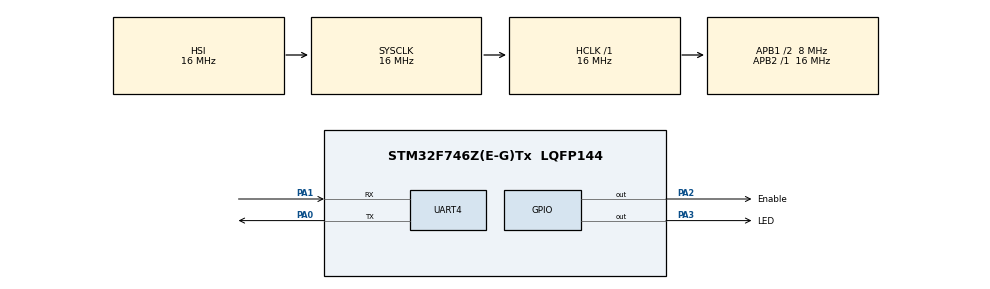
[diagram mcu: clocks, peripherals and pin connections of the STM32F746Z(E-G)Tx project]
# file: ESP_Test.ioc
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Mcu.Family=STM32F7
Mcu.Name=STM32F746Z(E-G)Tx
Mcu.Package=LQFP144
NVIC.PriorityGroup=NVIC_PRIORITYGROUP_4
PA0/WKUP.Mode=Asynchronous
PA0/WKUP.Signal=UART4_TX
PA1.Mode=Asynchronous
PA1.Signal=UART4_RX
PA2.GPIO_Label=Enable 
PA2.Signal=GPIO_Output
PA3.GPIO_Label=LED
PA3.Signal=GPIO_Output
ProjectManager.HeapSize=0x200
ProjectManager.StackSize=0x400
ProjectManager.TargetToolchain=SW4STM32
RCC.48MHZClocksFreq_Value=24000000
RCC.AHBFreq_Value=16000000
RCC.APB1CLKDivider=RCC_HCLK_DIV2
RCC.APB1Freq_Value=8000000
RCC.APB1TimFreq_Value=16000000
RCC.APB2Freq_Value=16000000
RCC.APB2TimFreq_Value=16000000
RCC.CortexFreq_Value=16000000
RCC.HCLKFreq_Value=16000000
RCC.HSE_VALUE=16000000
RCC.HSI_VALUE=16000000
RCC.LSE_VALUE=32768
RCC.PLLMUL=RCC_PLL_MUL9
RCC.PRESCALERUSB=RCC_USBCLKSOURCE_PLL_DIV1_5
RCC.SYSCLKFreq_VALUE=16000000
RCC.SYSCLKSourceVirtual=RCC_SYSCLKSOURCE_PLLCLK
RCC.USBFreq_Value=96000000
RCC.VCOOutputFreq_Value=192000000
UART4.WordLength=UART_WORDLENGTH_8B
board=NUCLEO-F746ZG

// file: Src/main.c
/**
  ******************************************************************************
  * File Name          : main.c
  * Description        : Main program body
  ******************************************************************************
  *
  * COPYRIGHT(c) 2016 STMicroelectronics
  *
  * Redistribution and use in source and binary forms, with or without modification,
  * are permitted provided that the following conditions are met:
  *   1. Redistributions of source code must retain the above copyright notice,
  *      this list of conditions and the following disclaimer.
  *   2. Redistributions in binary form must reproduce the above copyright notice,
  *      this list of conditions and the following disclaimer in the documentation
  *      and/or other materials provided with the distribution.
  *   3. Neither the name of STMicroelectronics nor the names of its contributors
  *      may be used to endorse or promote products derived from this software
  *      without specific prior written permission.
  *
  * THIS SOFTWARE IS PROVIDED BY THE COPYRIGHT HOLDERS AND CONTRIBUTORS "AS IS"
  * AND ANY EXPRESS OR IMPLIED WARRANTIES, INCLUDING, BUT NOT LIMITED TO, THE
  * IMPLIED WARRANTIES OF MERCHANTABILITY AND FITNESS FOR A PARTICULAR PURPOSE ARE
  * DISCLAIMED. IN NO EVENT SHALL THE COPYRIGHT HOLDER OR CONTRIBUTORS BE LIABLE
  * FOR ANY DIRECT, INDIRECT, INCIDENTAL, SPECIAL, EXEMPLARY, OR CONSEQUENTIAL
  * DAMAGES (INCLUDING, BUT NOT LIMITED TO, PROCUREMENT OF SUBSTITUTE GOODS OR
  * SERVICES; LOSS OF USE, DATA, OR PROFITS; OR BUSINESS INTERRUPTION) HOWEVER
  * CAUSED AND ON ANY THEORY OF LIABILITY, WHETHER IN CONTRACT, STRICT LIABILITY,
  * OR TORT (INCLUDING NEGLIGENCE OR OTHERWISE) ARISING IN ANY WAY OUT OF THE USE
  * OF THIS SOFTWARE, EVEN IF ADVISED OF THE POSSIBILITY OF SUCH DAMAGE.
  *
  ******************************************************************************
  */
#include "stm32f7xx_hal.h"
#include"stdlib.h"

UART_HandleTypeDef huart4;

/* USER CODE BEGIN PV */
/* Private variables ---------------------------------------------------------*/

/* USER CODE END PV */

void SystemClock_Config(void);
void Error_Handler(void);
static void MX_GPIO_Init(void);
static void MX_UART4_Init(void);

/* USER CODE BEGIN PFP */
/* Private function prototypes -----------------------------------------------*/

/* USER CODE END PFP */

/* USER CODE BEGIN 0 */
void Activety(void);
void EnableModule(void);
void DisableModule(void);
void TestModule(void);
void SetMode(void);
void GetcurrentMode(void);

/* USER CODE END 0 */

int main(void)
{

	/* Enable I-Cache-------------------------------------------------------------*/
	 SCB_EnableICache();
	/* Enable D-Cache-------------------------------------------------------------*/
	SCB_EnableDCache();
  /* MCU Configuration----------------------------------------------------------*/

  /* Reset of all peripherals, Initializes the Flash interface and the Systick. */
  HAL_Init();

  /* Configure the system clock */
  SystemClock_Config();

  /* Initialize all configured peripherals */
  MX_GPIO_Init();
  MX_UART4_Init();

  /* USER CODE BEGIN 2 */
  Activety();
  EnableModule();
  TestModule();
  DisableModule();
  Activety();
  /* USER CODE END 2 */

  /* Infinite loop */
  while (1)
  {

  }

}

/** System Clock Configuration
*/
void SystemClock_Config(void)
{

  RCC_OscInitTypeDef RCC_OscInitStruct;
  RCC_ClkInitTypeDef RCC_ClkInitStruct;
  RCC_PeriphCLKInitTypeDef PeriphClkInitStruct;

  __HAL_RCC_PWR_CLK_ENABLE();

  __HAL_PWR_VOLTAGESCALING_CONFIG(PWR_REGULATOR_VOLTAGE_SCALE3);

  RCC_OscInitStruct.OscillatorType = RCC_OSCILLATORTYPE_HSI;
  RCC_OscInitStruct.HSIState = RCC_HSI_ON;
  RCC_OscInitStruct.HSICalibrationValue = 16;
  RCC_OscInitStruct.PLL.PLLState = RCC_PLL_NONE;
  if (HAL_RCC_OscConfig(&RCC_OscInitStruct) != HAL_OK)
  {
    Error_Handler();
  }

  RCC_ClkInitStruct.ClockType = RCC_CLOCKTYPE_HCLK|RCC_CLOCKTYPE_SYSCLK
                              |RCC_CLOCKTYPE_PCLK1|RCC_CLOCKTYPE_PCLK2;
  RCC_ClkInitStruct.SYSCLKSource = RCC_SYSCLKSOURCE_HSI;
  RCC_ClkInitStruct.AHBCLKDivider = RCC_SYSCLK_DIV1;
  RCC_ClkInitStruct.APB1CLKDivider = RCC_HCLK_DIV2;
  RCC_ClkInitStruct.APB2CLKDivider = RCC_HCLK_DIV1;
  if (HAL_RCC_ClockConfig(&RCC_ClkInitStruct, FLASH_LATENCY_0) != HAL_OK)
  {
    Error_Handler();
  }

  PeriphClkInitStruct.PeriphClockSelection = RCC_PERIPHCLK_UART4;
  PeriphClkInitStruct.Uart4ClockSelection = RCC_UART4CLKSOURCE_PCLK1;
  if (HAL_RCCEx_PeriphCLKConfig(&PeriphClkInitStruct) != HAL_OK)
  {
    Error_Handler();
  }

  HAL_SYSTICK_Config(HAL_RCC_GetHCLKFreq()/1000);

  HAL_SYSTICK_CLKSourceConfig(SYSTICK_CLKSOURCE_HCLK);

  /* SysTick_IRQn interrupt configuration */
  HAL_NVIC_SetPriority(SysTick_IRQn, 0, 0);
}

/* UART4 init function */
static void MX_UART4_Init(void)
{

  huart4.Instance = UART4;
  huart4.Init.BaudRate = 115200;
  huart4.Init.WordLength = UART_WORDLENGTH_8B;
  huart4.Init.StopBits = UART_STOPBITS_1;
  huart4.Init.Parity = UART_PARITY_NONE;
  huart4.Init.Mode = UART_MODE_TX_RX;
  huart4.Init.HwFlowCtl = UART_HWCONTROL_NONE;
  huart4.Init.OverSampling = UART_OVERSAMPLING_16;
  huart4.Init.OneBitSampling = UART_ONE_BIT_SAMPLE_DISABLE;
  huart4.AdvancedInit.AdvFeatureInit = UART_ADVFEATURE_NO_INIT;
  if (HAL_UART_Init(&huart4) != HAL_OK)
  {
    Error_Handler();
  }

}

/** Configure pins as
        * Analog
        * Input
        * Output
        * EVENT_OUT
        * EXTI
*/
static void MX_GPIO_Init(void)
{

  GPIO_InitTypeDef GPIO_InitStruct;

  /* GPIO Ports Clock Enable */
  __HAL_RCC_GPIOA_CLK_ENABLE();

  /*Configure GPIO pin Output Level */
  HAL_GPIO_WritePin(GPIOA, Enable_Pin|LED_Pin, GPIO_PIN_RESET);

  /*Configure GPIO pins : Enable_Pin LED_Pin */
  GPIO_InitStruct.Pin = Enable_Pin|LED_Pin;
  GPIO_InitStruct.Mode = GPIO_MODE_OUTPUT_PP;
  GPIO_InitStruct.Pull = GPIO_NOPULL;
  GPIO_InitStruct.Speed = GPIO_SPEED_FREQ_LOW;
  HAL_GPIO_Init(GPIOA, &GPIO_InitStruct);

}

/* USER CODE BEGIN 4 */

void EnableModule(void)
{
	HAL_GPIO_WritePin(Enable_GPIO_Port,Enable_Pin,GPIO_PIN_SET);
}
void DisableModule(void)
{
	HAL_GPIO_WritePin(Enable_GPIO_Port,Enable_Pin,GPIO_PIN_RESET);
}
void TestModule(void)
{
	uint8_t AT_C[5] = "AT\r\n";
	uint8_t response[5]="";
	uint8_t x;
	uint8_t i =0;
	HAL_UART_Transmit(&huart4,AT_C,strlen(AT_C),HAL_MAX_DELAY);
	 do
	 {
		 HAL_UART_Receive(&huart4,&x,1,HAL_MAX_DELAY);
		 response[i++]=x;
	}while(x != NULL);
	i = 0;
	if(strcmp(response,"OK")==0)
	{
		HAL_GPIO_WritePin(LED_GPIO_Port,LED_Pin,GPIO_PIN_SET);
	}
	else
	{
		HAL_GPIO_WritePin(LED_GPIO_Port,LED_Pin,GPIO_PIN_RESET);
	}
}
void Activety(void)
{
	HAL_GPIO_WritePin(LED_GPIO_Port,LED_Pin,GPIO_PIN_SET);
	HAL_Delay(500);
	HAL_GPIO_WritePin(LED_GPIO_Port,LED_Pin,GPIO_PIN_RESET);
}

/* USER CODE END 4
 *  */

 void Error_Handler(void)
{
  while(1)
  {
  }
}

/************************ (C) COPYRIGHT STMicroelectronics *****END OF FILE****/
